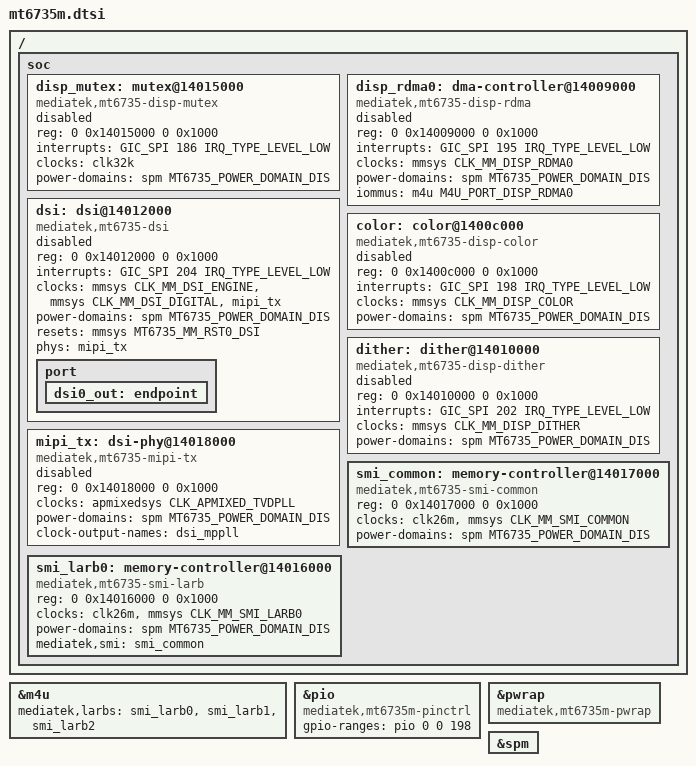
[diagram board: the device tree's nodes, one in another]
// SPDX-License-Identifier: BSD-3-Clause

/dts-v1/;

#include "mt6735.dtsi"

/delete-node/ &disp_rdma0;
/delete-node/ &color;
/delete-node/ &dither;
/delete-node/ &dsi;
/delete-node/ &disp_mutex;
/delete-node/ &mipi_tx;
/delete-node/ &smi_common;
/delete-node/ &smi_larb0;
/delete-node/ &smi_larb3;

/ {
	soc {
		disp_mutex: mutex@14015000 {
			compatible = "mediatek,mt6735-disp-mutex";
			reg = <0 0x14015000 0 0x1000>;

			interrupts = <GIC_SPI 186 IRQ_TYPE_LEVEL_LOW>;

			clocks = <&clk32k>;

			power-domains = <&spm MT6735_POWER_DOMAIN_DIS>;

			status = "disabled";
		};

		disp_rdma0: dma-controller@14009000 {
			compatible = "mediatek,mt6735-disp-rdma", "mediatek,mt2701-disp-rdma";
			reg = <0 0x14009000 0 0x1000>;

			interrupts = <GIC_SPI 195 IRQ_TYPE_LEVEL_LOW>;

			clocks = <&mmsys CLK_MM_DISP_RDMA0>;

			power-domains = <&spm MT6735_POWER_DOMAIN_DIS>;

			iommus = <&m4u M4U_PORT_DISP_RDMA0>;

			status = "disabled";
		};

		dsi: dsi@14012000 {
			compatible = "mediatek,mt6735-dsi", "mediatek,mt8173-dsi";
			reg = <0 0x14012000 0 0x1000>;

			interrupts = <GIC_SPI 204 IRQ_TYPE_LEVEL_LOW>;

			clocks = <&mmsys CLK_MM_DSI_ENGINE>,
				 <&mmsys CLK_MM_DSI_DIGITAL>,
				 <&mipi_tx>;
			clock-names = "engine", "digital", "hs";

			power-domains = <&spm MT6735_POWER_DOMAIN_DIS>;

			resets = <&mmsys MT6735_MM_RST0_DSI>;

			phys = <&mipi_tx>;
			phy-names = "dphy";

			#address-cells = <1>;
			#size-cells = <0>;

			status = "disabled";

			port {
				dsi0_out: endpoint { };
			};
		};

		color: color@1400c000 {
			compatible = "mediatek,mt6735-disp-color", "mediatek,mt8167-disp-color";
			reg = <0 0x1400c000 0 0x1000>;

			interrupts = <GIC_SPI 198 IRQ_TYPE_LEVEL_LOW>;

			clocks = <&mmsys CLK_MM_DISP_COLOR>;

			power-domains = <&spm MT6735_POWER_DOMAIN_DIS>;

			status = "disabled";
		};

		dither: dither@14010000 {
			compatible = "mediatek,mt6735-disp-dither", "mediatek,mt8183-disp-dither";
			reg = <0 0x14010000 0 0x1000>;

			interrupts = <GIC_SPI 202 IRQ_TYPE_LEVEL_LOW>;

			clocks = <&mmsys CLK_MM_DISP_DITHER>;

			power-domains = <&spm MT6735_POWER_DOMAIN_DIS>;

			status = "disabled";
		};

		mipi_tx: dsi-phy@14018000 {
			compatible = "mediatek,mt6735-mipi-tx", "mediatek,mt8173-mipi-tx";
			reg = <0 0x14018000 0 0x1000>;

			clocks = <&apmixedsys CLK_APMIXED_TVDPLL>;

			power-domains = <&spm MT6735_POWER_DOMAIN_DIS>;

			#clock-cells = <0>;
			clock-output-names = "dsi_mppll";

			#phy-cells = <0>;

			status = "disabled";
		};

		smi_common: memory-controller@14017000 {
			compatible = "mediatek,mt6735-smi-common";
			reg = <0 0x14017000 0 0x1000>;

			clocks = <&clk26m>,
				 <&mmsys CLK_MM_SMI_COMMON>;
			clock-names = "apb", "smi";

			power-domains = <&spm MT6735_POWER_DOMAIN_DIS>;
		};

		smi_larb0: memory-controller@14016000 {
			compatible = "mediatek,mt6735-smi-larb";
			reg = <0 0x14016000 0 0x1000>;

			clocks = <&clk26m>,
				 <&mmsys CLK_MM_SMI_LARB0>;
			clock-names = "apb", "smi";

			power-domains = <&spm MT6735_POWER_DOMAIN_DIS>;

			mediatek,smi = <&smi_common>;
		};
	};
};

&m4u {
	mediatek,larbs = <&smi_larb0>, <&smi_larb1>, <&smi_larb2>;
};

&pio {
	compatible = "mediatek,mt6735m-pinctrl";
	gpio-ranges = <&pio 0 0 198>;

	/delete-node/ mmc2_pins_default;
	/delete-node/ mmc2_pins_uhs;
};

&pwrap {
	compatible = "mediatek,mt6735m-pwrap";
};

/* This domain does not come up on MT6735M, and the only thing using it on MT6735M is LARB3 which does not exist */
&spm {
	/delete-node/ power-domain@MT6735_POWER_DOMAIN_VEN;
};
